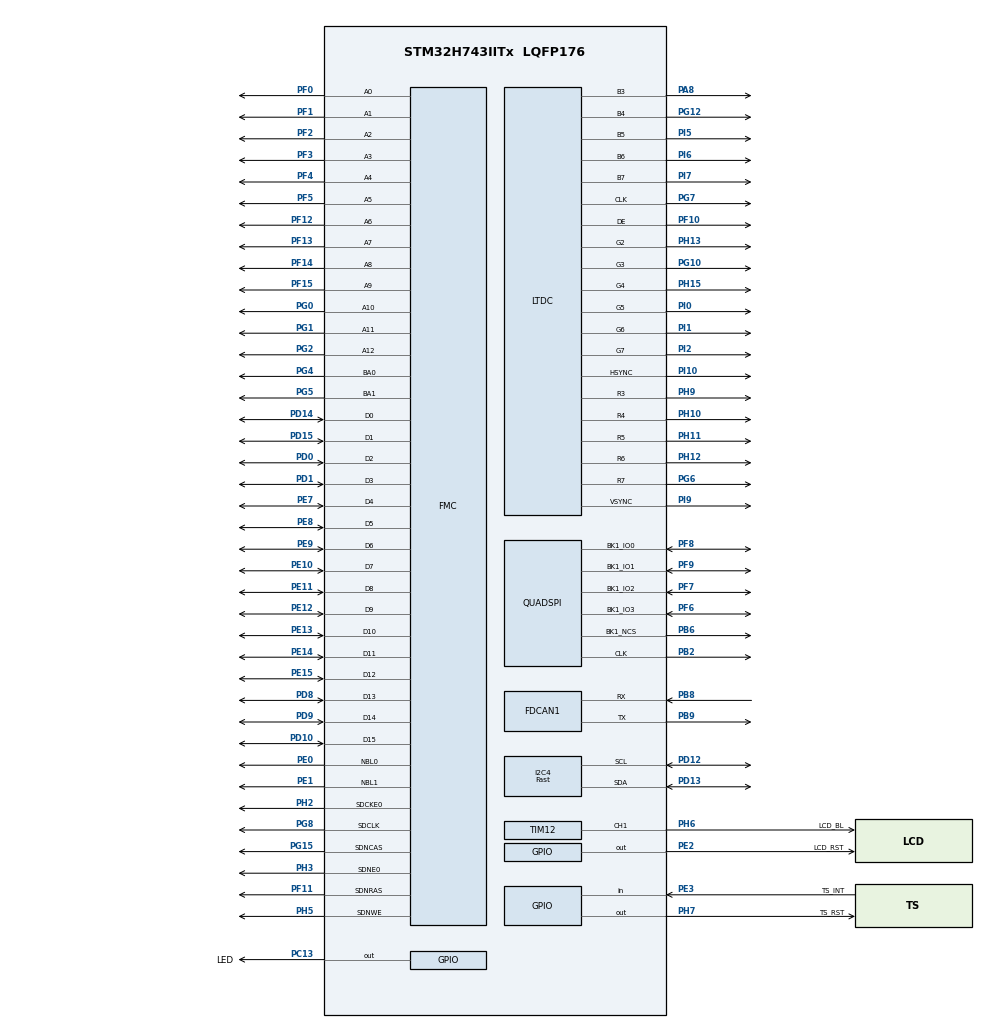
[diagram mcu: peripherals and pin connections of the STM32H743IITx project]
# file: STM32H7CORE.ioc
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CORTEX_M7.AccessPermission_S-Cortex_Memory_Protection_Unit_Region1_Settings_S=MPU_REGION_FULL_ACCESS
CORTEX_M7.BaseAddress_S-Cortex_Memory_Protection_Unit_Region1_Settings_S=0xC0000000
CORTEX_M7.CPU_DCache=Enabled
CORTEX_M7.CPU_ICache=Enabled
CORTEX_M7.Enable_S-Cortex_Memory_Protection_Unit_Region1_Settings_S=MPU_REGION_ENABLE
CORTEX_M7.IsCacheable_S-Cortex_Memory_Protection_Unit_Region1_Settings_S=MPU_ACCESS_CACHEABLE
CORTEX_M7.IsShareable_S-Cortex_Memory_Protection_Unit_Region1_Settings_S=MPU_ACCESS_SHAREABLE
CORTEX_M7.Size_S-Cortex_Memory_Protection_Unit_Region1_Settings_S=MPU_REGION_SIZE_32MB
CORTEX_M7.default_mode_Activation=1
DMA2D.ColorMode=DMA2D_OUTPUT_RGB565
FDCAN1.CalculateBaudRateNominal=500000
FDCAN1.CalculateTimeBitNominal=2000
FDCAN1.CalculateTimeQuantumNominal=50.0
FDCAN1.DataPrescaler=8
FDCAN1.DataSyncJumpWidth=5
FDCAN1.DataTimeSeg1=14
FDCAN1.DataTimeSeg2=5
FDCAN1.Mode=FDCAN_MODE_INTERNAL_LOOPBACK
FDCAN1.NominalPrescaler=4
FDCAN1.NominalSyncJumpWidth=5
FDCAN1.NominalTimeSeg1=34
FDCAN1.NominalTimeSeg2=5
FDCAN1.RxFifo0ElmtsNbr=1
FDCAN1.StdFiltersNbr=1
FDCAN1.TxFifoQueueElmtsNbr=1
FMC.CASLatency1=FMC_SDRAM_CAS_LATENCY_3
FMC.ExitSelfRefreshDelay1=7
FMC.LoadToActiveDelay1=2
FMC.RCDDelay1=2
FMC.RPDelay1=2
FMC.ReadBurst1=FMC_SDRAM_RBURST_ENABLE
FMC.RowCycleDelay1=7
FMC.SDClockPeriod1=FMC_SDRAM_CLOCK_PERIOD_2
FMC.SelfRefreshTime1=4
FMC.WriteRecoveryTime1=3
FREERTOS.Mutexes01=lvglMutex,Dynamic,NULL,Available
FREERTOS.Queues01=backlightQueue,4,uint16_t,0,Dynamic,NULL,NULL;canRxQueue,16,CAN_RxMessageTypeDef,0,Dynamic,NULL,NULL
FREERTOS.Tasks01=debugTask,24,128,DebugTask,Default,NULL,Dynamic,NULL,NULL;lvglTask,25,2048,LvglTask,Default,NULL,Dynamic,NULL,NULL;backlightTask,8,128,BacklightTask,Default,NULL,Dynamic,NULL,NULL;canRxTask,8,1024,CanRxTask,Default,NULL,Dynamic,NULL,NULL;weakTask,8,128,WeakTask,As weak,NULL,Dynamic,NULL,NULL;externTask,8,128,ExternTask,As external,NULL,Dynamic,NULL,NULL
FREERTOS.configENABLE_FPU=1
FREERTOS.configTOTAL_HEAP_SIZE=64000
I2C4.I2C_Speed_Mode=I2C_Fast
I2C4.Timing=0x00B03FDB
LTDC.ActiveH=600
LTDC.ActiveW=1024
LTDC.Alpha_L0=255
LTDC.FBStartAdress_L0=0xC0000000
LTDC.HBP=46
LTDC.HFP=40
LTDC.HSync=1
LTDC.ImageHeight_L0=600
LTDC.ImageWidth_L0=1024
LTDC.Layers=0
LTDC.PixelFormat_L0=LTDC_PIXEL_FORMAT_RGB565
LTDC.VBP=24
LTDC.VFP=10
LTDC.VSync=2
LTDC.WindowX1_L0=1024
LTDC.WindowY1_L0=600
Mcu.Family=STM32H7
Mcu.Name=STM32H743IITx
Mcu.Package=LQFP176
NVIC.FDCAN1_IT0_IRQn=true\:5\:0\:false\:false\:true\:true\:true\:true\:true
NVIC.PriorityGroup=NVIC_PRIORITYGROUP_4
NVIC.TIM6_DAC_IRQn=true\:15\:0\:false\:false\:true\:false\:false\:true\:true
NVIC.TimeBase=TIM6_DAC_IRQn
NVIC.TimeBaseIP=TIM6
PA13\ (JTMS/SWDIO).Mode=Serial_Wire
PA13\ (JTMS/SWDIO).Signal=DEBUG_JTMS-SWDIO
PA14\ (JTCK/SWCLK).Mode=Serial_Wire
PA14\ (JTCK/SWCLK).Signal=DEBUG_JTCK-SWCLK
PA8.GPIO_Speed=GPIO_SPEED_FREQ_VERY_HIGH
PA8.Mode=RGB565
PA8.Signal=LTDC_B3
PB2.Mode=Single Bank 1
PB2.Signal=QUADSPI_CLK
PB6.Mode=Single Bank 1
PB6.Signal=QUADSPI_BK1_NCS
PB8.GPIO_Speed=GPIO_SPEED_FREQ_VERY_HIGH
PB8.Mode=FDCAN_Activate
PB8.Signal=FDCAN1_RX
PB9.GPIO_Speed=GPIO_SPEED_FREQ_VERY_HIGH
PB9.Mode=FDCAN_Activate
PB9.Signal=FDCAN1_TX
PC13.GPIO_Label=LED
PC13.Signal=GPIO_Output
PC14-OSC32_IN\ (OSC32_IN).Mode=LSE-External-Oscillator
PC14-OSC32_IN\ (OSC32_IN).Signal=RCC_OSC32_IN
PC15-OSC32_OUT\ (OSC32_OUT).Mode=LSE-External-Oscillator
PC15-OSC32_OUT\ (OSC32_OUT).Signal=RCC_OSC32_OUT
PD0.Signal=FMC_D2_DA2
PD1.Signal=FMC_D3_DA3
PD10.Signal=FMC_D15_DA15
PD12.Mode=I2C
PD12.Signal=I2C4_SCL
PD13.Mode=I2C
PD13.Signal=I2C4_SDA
PD14.Signal=FMC_D0_DA0
PD15.Signal=FMC_D1_DA1
PD8.Signal=FMC_D13_DA13
PD9.Signal=FMC_D14_DA14
PE0.Signal=FMC_NBL0
PE1.Signal=FMC_NBL1
PE10.Signal=FMC_D7_DA7
PE11.Signal=FMC_D8_DA8
PE12.Signal=FMC_D9_DA9
PE13.Signal=FMC_D10_DA10
PE14.Signal=FMC_D11_DA11
PE15.Signal=FMC_D12_DA12
PE2.GPIO_Label=LCD_RST
PE2.PinState=GPIO_PIN_SET
PE2.Signal=GPIO_Output
PE3.GPIO_Label=TS_INT
PE3.Signal=GPIO_Input
PE7.Signal=FMC_D4_DA4
PE8.Signal=FMC_D5_DA5
PE9.Signal=FMC_D6_DA6
PF0.Signal=FMC_A0
PF1.Signal=FMC_A1
PF10.GPIO_Speed=GPIO_SPEED_FREQ_VERY_HIGH
PF10.Mode=RGB565
PF10.Signal=LTDC_DE
PF11.Signal=FMC_SDNRAS
PF12.Signal=FMC_A6
PF13.Signal=FMC_A7
PF14.Signal=FMC_A8
PF15.Signal=FMC_A9
PF2.Signal=FMC_A2
PF3.Signal=FMC_A3
PF4.Signal=FMC_A4
PF5.Signal=FMC_A5
PF6.Mode=Single Bank 1
PF6.Signal=QUADSPI_BK1_IO3
PF7.Mode=Single Bank 1
PF7.Signal=QUADSPI_BK1_IO2
PF8.Mode=Single Bank 1
PF8.Signal=QUADSPI_BK1_IO0
PF9.Mode=Single Bank 1
PF9.Signal=QUADSPI_BK1_IO1
PG0.Signal=FMC_A10
PG1.Signal=FMC_A11
PG10.GPIO_Speed=GPIO_SPEED_FREQ_VERY_HIGH
PG10.Mode=RGB565
PG10.Signal=LTDC_G3
PG12.GPIO_Speed=GPIO_SPEED_FREQ_VERY_HIGH
PG12.Mode=RGB565
PG12.Signal=LTDC_B4
PG15.Signal=FMC_SDNCAS
PG2.Signal=FMC_A12
PG4.Signal=FMC_A14_BA0
PG5.Signal=FMC_A15_BA1
PG6.GPIO_Speed=GPIO_SPEED_FREQ_VERY_HIGH
PG6.Mode=RGB565
PG6.Signal=LTDC_R7
PG7.GPIO_Speed=GPIO_SPEED_FREQ_VERY_HIGH
PG7.Mode=RGB565
PG7.Signal=LTDC_CLK
PG8.Signal=FMC_SDCLK
PH0-OSC_IN\ (PH0).Mode=HSE-External-Oscillator
PH0-OSC_IN\ (PH0).Signal=RCC_OSC_IN
PH1-OSC_OUT\ (PH1).Mode=HSE-External-Oscillator
PH1-OSC_OUT\ (PH1).Signal=RCC_OSC_OUT
PH10.GPIO_Speed=GPIO_SPEED_FREQ_VERY_HIGH
PH10.Mode=RGB565
PH10.Signal=LTDC_R4
PH11.GPIO_Speed=GPIO_SPEED_FREQ_VERY_HIGH
PH11.Mode=RGB565
PH11.Signal=LTDC_R5
PH12.GPIO_Speed=GPIO_SPEED_FREQ_VERY_HIGH
PH12.Mode=RGB565
PH12.Signal=LTDC_R6
PH13.GPIO_Speed=GPIO_SPEED_FREQ_VERY_HIGH
PH13.Mode=RGB565
PH13.Signal=LTDC_G2
PH15.GPIO_Speed=GPIO_SPEED_FREQ_VERY_HIGH
PH15.Mode=RGB565
PH15.Signal=LTDC_G4
PH2.Mode=SdramChipSelect1_1
PH2.Signal=FMC_SDCKE0
PH3.Mode=SdramChipSelect1_1
PH3.Signal=FMC_SDNE0
PH5.Signal=FMC_SDNWE
PH6.GPIO_Label=LCD_BL
PH6.Signal=S_TIM12_CH1
PH7.GPIO_Label=TS_RST
PH7.Signal=GPIO_Output
PH9.GPIO_Speed=GPIO_SPEED_FREQ_VERY_HIGH
PH9.Mode=RGB565
PH9.Signal=LTDC_R3
PI0.GPIO_Speed=GPIO_SPEED_FREQ_VERY_HIGH
PI0.Mode=RGB565
PI0.Signal=LTDC_G5
PI1.GPIO_Speed=GPIO_SPEED_FREQ_VERY_HIGH
PI1.Mode=RGB565
PI1.Signal=LTDC_G6
PI10.GPIO_Speed=GPIO_SPEED_FREQ_VERY_HIGH
PI10.Mode=RGB565
PI10.Signal=LTDC_HSYNC
PI2.GPIO_Speed=GPIO_SPEED_FREQ_VERY_HIGH
PI2.Mode=RGB565
PI2.Signal=LTDC_G7
PI5.GPIO_Speed=GPIO_SPEED_FREQ_VERY_HIGH
PI5.Mode=RGB565
PI5.Signal=LTDC_B5
PI6.GPIO_Speed=GPIO_SPEED_FREQ_VERY_HIGH
PI6.Mode=RGB565
PI6.Signal=LTDC_B6
PI7.GPIO_Speed=GPIO_SPEED_FREQ_VERY_HIGH
PI7.Mode=RGB565
PI7.Signal=LTDC_B7
PI9.GPIO_Speed=GPIO_SPEED_FREQ_VERY_HIGH
PI9.Mode=RGB565
PI9.Signal=LTDC_VSYNC
ProjectManager.HeapSize=0x200
ProjectManager.StackSize=0x400
ProjectManager.TargetToolchain=CMake
QUADSPI.ClockPrescaler=1
QUADSPI.FifoThreshold=4
QUADSPI.FlashSize=23
QUADSPI.SampleShifting=QSPI_SAMPLE_SHIFTING_NONE
RCC.ADCFreq_Value=50390625
RCC.APB1Freq_Value=120000000
RCC.APB2Freq_Value=120000000
RCC.APB3Freq_Value=120000000
RCC.APB4Freq_Value=120000000
RCC.CortexFreq_Value=480000000
RCC.D1PPRE=RCC_APB3_DIV2
RCC.D2PPRE1=RCC_APB1_DIV2
RCC.D2PPRE2=RCC_APB2_DIV2
RCC.D3PPRE=RCC_APB4_DIV2
RCC.DIVM1=5
RCC.DIVM3=1
RCC.DIVN1=192
RCC.DIVN3=6
RCC.DIVQ1=12
RCC.DIVR3=6
RCC.HCLKFreq_Value=240000000
RCC.HPRE=RCC_HCLK_DIV2
RCC.PLL3FRACN=0
RCC.PLLFRACN=0
RCC.PLLSourceVirtual=RCC_PLLSOURCE_HSE
RCC.SYSCLKFreq_VALUE=480000000
RCC.SYSCLKSource=RCC_SYSCLKSOURCE_PLLCLK
RCC.USBFreq_Value=80000000
SH.FMC_A0.0=FMC_A0,13b-sda1
SH.FMC_A1.0=FMC_A1,13b-sda1
SH.FMC_A10.0=FMC_A10,13b-sda1
SH.FMC_A11.0=FMC_A11,13b-sda1
SH.FMC_A12.0=FMC_A12,13b-sda1
SH.FMC_A14_BA0.0=FMC_BA0,FourSdramBanks1
SH.FMC_A15_BA1.0=FMC_BA1,FourSdramBanks1
SH.FMC_A2.0=FMC_A2,13b-sda1
SH.FMC_A3.0=FMC_A3,13b-sda1
SH.FMC_A4.0=FMC_A4,13b-sda1
SH.FMC_A5.0=FMC_A5,13b-sda1
SH.FMC_A6.0=FMC_A6,13b-sda1
SH.FMC_A7.0=FMC_A7,13b-sda1
SH.FMC_A8.0=FMC_A8,13b-sda1
SH.FMC_A9.0=FMC_A9,13b-sda1
SH.FMC_D0_DA0.0=FMC_D0,sd-16b-d1
SH.FMC_D10_DA10.0=FMC_D10,sd-16b-d1
SH.FMC_D11_DA11.0=FMC_D11,sd-16b-d1
SH.FMC_D12_DA12.0=FMC_D12,sd-16b-d1
SH.FMC_D13_DA13.0=FMC_D13,sd-16b-d1
SH.FMC_D14_DA14.0=FMC_D14,sd-16b-d1
SH.FMC_D15_DA15.0=FMC_D15,sd-16b-d1
SH.FMC_D1_DA1.0=FMC_D1,sd-16b-d1
SH.FMC_D2_DA2.0=FMC_D2,sd-16b-d1
SH.FMC_D3_DA3.0=FMC_D3,sd-16b-d1
SH.FMC_D4_DA4.0=FMC_D4,sd-16b-d1
SH.FMC_D5_DA5.0=FMC_D5,sd-16b-d1
SH.FMC_D6_DA6.0=FMC_D6,sd-16b-d1
SH.FMC_D7_DA7.0=FMC_D7,sd-16b-d1
SH.FMC_D8_DA8.0=FMC_D8,sd-16b-d1
SH.FMC_D9_DA9.0=FMC_D9,sd-16b-d1
SH.FMC_NBL0.0=FMC_NBL0,Sd2ByteEnable1
SH.FMC_NBL1.0=FMC_NBL1,Sd2ByteEnable1
SH.FMC_SDCLK.0=FMC_SDCLK,13b-sda1
SH.FMC_SDNCAS.0=FMC_SDNCAS,13b-sda1
SH.FMC_SDNRAS.0=FMC_SDNRAS,13b-sda1
SH.FMC_SDNWE.0=FMC_SDNWE,13b-sda1
SH.S_TIM12_CH1.0=TIM12_CH1,PWM Generation1 CH1
TIM12.Channel-PWM\ Generation1\ CH1=TIM_CHANNEL_1
TIM12.Period=99
TIM12.Prescaler=9999
TIM12.Pulse-PWM\ Generation1\ CH1=20
VP_DMA2D_VS_DMA2D.Mode=DMA2D_Activate
VP_FREERTOS_VS_CMSIS_V2.Mode=CMSIS_V2
VP_MEMORYMAP_VS_MEMORYMAP.Mode=CurAppReg
VP_SYS_VS_tim6.Mode=TIM6
VP_TIM12_VS_ClockSourceINT.Mode=Internal
board=custom

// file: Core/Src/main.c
/* USER CODE BEGIN Header */
/**
  ******************************************************************************
  * @file           : main.c
  * @brief          : Main program body
  ******************************************************************************
  * @attention
  *
  * Copyright (c) 2025 STMicroelectronics.
  * All rights reserved.
  *
  * This software is licensed under terms that can be found in the LICENSE file
  * in the root directory of this software component.
  * If no LICENSE file comes with this software, it is provided AS-IS.
  *
  ******************************************************************************
  */
/* USER CODE END Header */
#include "main.h"
#include "cmsis_os.h"
#include "dma2d.h"
#include "fdcan.h"
#include "i2c.h"
#include "ltdc.h"
#include "quadspi.h"
#include "tim.h"
#include "gpio.h"
#include "fmc.h"

/* USER CODE BEGIN Includes */
#include <string.h>

#include "bsp.h"
/* USER CODE END Includes */

/* USER CODE BEGIN PV */
extern osMessageQueueId_t canRxQueueHandle;
extern osThreadId_t externTaskHandle;
/* USER CODE END PV */

void SystemClock_Config(void);
static void MPU_Config(void);
void MX_FREERTOS_Init(void);

/* USER CODE BEGIN 0 */
void HAL_FDCAN_RxFifo0Callback(FDCAN_HandleTypeDef *hfdcan, uint32_t RxFifo0ITs) {
    if ((RxFifo0ITs & FDCAN_IT_RX_FIFO0_NEW_MESSAGE) != RESET) {
        FDCAN_RxHeaderTypeDef RxHeader;
        uint8_t RxBuffer[8];
        HAL_FDCAN_GetRxMessage(hfdcan, FDCAN_RX_FIFO0, &RxHeader, RxBuffer);

        CAN_RxMessageTypeDef CAN_RxMessage;
        CAN_RxMessage.ID = RxHeader.Identifier;
        memcpy(CAN_RxMessage.Data, RxBuffer, 8);
        osMessageQueuePut(canRxQueueHandle, &CAN_RxMessage, 0, 0);
    }
}

void ExternTask(void const * argument) {
  osThreadSuspend(externTaskHandle);
  for (;;) {
    HAL_GPIO_TogglePin(LED_GPIO_Port, LED_Pin);
    osDelay(500);
  }
}
/* USER CODE END 0 */

int main(void)
{

  /* MPU Configuration--------------------------------------------------------*/
  MPU_Config();

  /* Enable the CPU Cache */

  /* Enable I-Cache---------------------------------------------------------*/
  SCB_EnableICache();

  /* Enable D-Cache---------------------------------------------------------*/
  SCB_EnableDCache();

  /* MCU Configuration--------------------------------------------------------*/

  /* Reset of all peripherals, Initializes the Flash interface and the Systick. */
  HAL_Init();

  /* Configure the system clock */
  SystemClock_Config();

  /* Initialize all configured peripherals */
  MX_GPIO_Init();
  MX_FMC_Init();
  MX_I2C4_Init();
  MX_LTDC_Init();
  MX_DMA2D_Init();
  MX_TIM12_Init();
  MX_FDCAN1_Init();
  MX_QUADSPI_Init();
  /* USER CODE BEGIN 2 */
    BSP_Init();
    HAL_FDCAN_Start(&hfdcan1);
    HAL_FDCAN_ActivateNotification(&hfdcan1, FDCAN_IT_RX_FIFO0_NEW_MESSAGE, 0);
  /* USER CODE END 2 */

  /* Init scheduler */
  osKernelInitialize();  /* Call init function for freertos objects (in cmsis_os2.c) */
  MX_FREERTOS_Init();

  /* Start scheduler */
  osKernelStart();

  /* We should never get here as control is now taken by the scheduler */

  /* Infinite loop */
    while (1) {

    }
}

void SystemClock_Config(void)
{
  RCC_OscInitTypeDef RCC_OscInitStruct = {0};
  RCC_ClkInitTypeDef RCC_ClkInitStruct = {0};

  /** Supply configuration update enable
  */
  HAL_PWREx_ConfigSupply(PWR_LDO_SUPPLY);

  /** Configure the main internal regulator output voltage
  */
  __HAL_PWR_VOLTAGESCALING_CONFIG(PWR_REGULATOR_VOLTAGE_SCALE0);

  while(!__HAL_PWR_GET_FLAG(PWR_FLAG_VOSRDY)) {}

  /** Initializes the RCC Oscillators according to the specified parameters
  * in the RCC_OscInitTypeDef structure.
  */
  RCC_OscInitStruct.OscillatorType = RCC_OSCILLATORTYPE_HSE;
  RCC_OscInitStruct.HSEState = RCC_HSE_ON;
  RCC_OscInitStruct.PLL.PLLState = RCC_PLL_ON;
  RCC_OscInitStruct.PLL.PLLSource = RCC_PLLSOURCE_HSE;
  RCC_OscInitStruct.PLL.PLLM = 5;
  RCC_OscInitStruct.PLL.PLLN = 192;
  RCC_OscInitStruct.PLL.PLLP = 2;
  RCC_OscInitStruct.PLL.PLLQ = 12;
  RCC_OscInitStruct.PLL.PLLR = 2;
  RCC_OscInitStruct.PLL.PLLRGE = RCC_PLL1VCIRANGE_2;
  RCC_OscInitStruct.PLL.PLLVCOSEL = RCC_PLL1VCOWIDE;
  RCC_OscInitStruct.PLL.PLLFRACN = 0;
  if (HAL_RCC_OscConfig(&RCC_OscInitStruct) != HAL_OK)
  {
    Error_Handler();
  }

  /** Initializes the CPU, AHB and APB buses clocks
  */
  RCC_ClkInitStruct.ClockType = RCC_CLOCKTYPE_HCLK|RCC_CLOCKTYPE_SYSCLK
                              |RCC_CLOCKTYPE_PCLK1|RCC_CLOCKTYPE_PCLK2
                              |RCC_CLOCKTYPE_D3PCLK1|RCC_CLOCKTYPE_D1PCLK1;
  RCC_ClkInitStruct.SYSCLKSource = RCC_SYSCLKSOURCE_PLLCLK;
  RCC_ClkInitStruct.SYSCLKDivider = RCC_SYSCLK_DIV1;
  RCC_ClkInitStruct.AHBCLKDivider = RCC_HCLK_DIV2;
  RCC_ClkInitStruct.APB3CLKDivider = RCC_APB3_DIV2;
  RCC_ClkInitStruct.APB1CLKDivider = RCC_APB1_DIV2;
  RCC_ClkInitStruct.APB2CLKDivider = RCC_APB2_DIV2;
  RCC_ClkInitStruct.APB4CLKDivider = RCC_APB4_DIV2;

  if (HAL_RCC_ClockConfig(&RCC_ClkInitStruct, FLASH_LATENCY_4) != HAL_OK)
  {
    Error_Handler();
  }
}

 /* MPU Configuration */

void MPU_Config(void)
{
  MPU_Region_InitTypeDef MPU_InitStruct = {0};

  /* Disables the MPU */
  HAL_MPU_Disable();

  /** Initializes and configures the Region and the memory to be protected
  */
  MPU_InitStruct.Enable = MPU_REGION_ENABLE;
  MPU_InitStruct.Number = MPU_REGION_NUMBER0;
  MPU_InitStruct.BaseAddress = 0x0;
  MPU_InitStruct.Size = MPU_REGION_SIZE_4GB;
  MPU_InitStruct.SubRegionDisable = 0x87;
  MPU_InitStruct.TypeExtField = MPU_TEX_LEVEL0;
  MPU_InitStruct.AccessPermission = MPU_REGION_NO_ACCESS;
  MPU_InitStruct.DisableExec = MPU_INSTRUCTION_ACCESS_DISABLE;
  MPU_InitStruct.IsShareable = MPU_ACCESS_SHAREABLE;
  MPU_InitStruct.IsCacheable = MPU_ACCESS_NOT_CACHEABLE;
  MPU_InitStruct.IsBufferable = MPU_ACCESS_NOT_BUFFERABLE;

  HAL_MPU_ConfigRegion(&MPU_InitStruct);

  /** Initializes and configures the Region and the memory to be protected
  */
  MPU_InitStruct.Number = MPU_REGION_NUMBER1;
  MPU_InitStruct.BaseAddress = 0xC0000000;
  MPU_InitStruct.Size = MPU_REGION_SIZE_32MB;
  MPU_InitStruct.SubRegionDisable = 0x0;
  MPU_InitStruct.AccessPermission = MPU_REGION_FULL_ACCESS;
  MPU_InitStruct.DisableExec = MPU_INSTRUCTION_ACCESS_ENABLE;
  MPU_InitStruct.IsCacheable = MPU_ACCESS_CACHEABLE;

  HAL_MPU_ConfigRegion(&MPU_InitStruct);
  /* Enables the MPU */
  HAL_MPU_Enable(MPU_PRIVILEGED_DEFAULT);

}

void HAL_TIM_PeriodElapsedCallback(TIM_HandleTypeDef *htim)
{
  if (htim->Instance == TIM6)
  {
    HAL_IncTick();
  }
}

void Error_Handler(void)
{
    __disable_irq();
    while (1) {
    }
}

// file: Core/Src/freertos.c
/* USER CODE BEGIN Header */
/**
  ******************************************************************************
  * File Name          : freertos.c
  * Description        : Code for freertos applications
  ******************************************************************************
  * @attention
  *
  * Copyright (c) 2025 STMicroelectronics.
  * All rights reserved.
  *
  * This software is licensed under terms that can be found in the LICENSE file
  * in the root directory of this software component.
  * If no LICENSE file comes with this software, it is provided AS-IS.
  *
  ******************************************************************************
  */
/* USER CODE END Header */

#include "FreeRTOS.h"
#include "task.h"
#include "main.h"
#include "cmsis_os.h"

/* USER CODE BEGIN Includes */
#include "lv_port_display.h"
#include "ui.h"
#include "actions.h"
#include "tim.h"
#include "fdcan.h"
/* USER CODE END Includes */

/* USER CODE BEGIN Variables */
uint8_t can_data_msg = 0;
/* USER CODE END Variables */
/* Definitions for debugTask */
osThreadId_t debugTaskHandle;
const osThreadAttr_t debugTask_attributes = {
  .name = "debugTask",
  .stack_size = 128 * 4,
  .priority = (osPriority_t) osPriorityNormal,
};
/* Definitions for lvglTask */
osThreadId_t lvglTaskHandle;
const osThreadAttr_t lvglTask_attributes = {
  .name = "lvglTask",
  .stack_size = 2048 * 4,
  .priority = (osPriority_t) osPriorityNormal1,
};
/* Definitions for backlightTask */
osThreadId_t backlightTaskHandle;
const osThreadAttr_t backlightTask_attributes = {
  .name = "backlightTask",
  .stack_size = 128 * 4,
  .priority = (osPriority_t) osPriorityLow,
};
/* Definitions for canRxTask */
osThreadId_t canRxTaskHandle;
const osThreadAttr_t canRxTask_attributes = {
  .name = "canRxTask",
  .stack_size = 1024 * 4,
  .priority = (osPriority_t) osPriorityLow,
};
/* Definitions for weakTask */
osThreadId_t weakTaskHandle;
const osThreadAttr_t weakTask_attributes = {
  .name = "weakTask",
  .stack_size = 128 * 4,
  .priority = (osPriority_t) osPriorityLow,
};
/* Definitions for externTask */
osThreadId_t externTaskHandle;
const osThreadAttr_t externTask_attributes = {
  .name = "externTask",
  .stack_size = 128 * 4,
  .priority = (osPriority_t) osPriorityLow,
};
/* Definitions for backlightQueue */
osMessageQueueId_t backlightQueueHandle;
const osMessageQueueAttr_t backlightQueue_attributes = {
  .name = "backlightQueue"
};
/* Definitions for canRxQueue */
osMessageQueueId_t canRxQueueHandle;
const osMessageQueueAttr_t canRxQueue_attributes = {
  .name = "canRxQueue"
};
/* Definitions for lvglMutex */
osMutexId_t lvglMutexHandle;
const osMutexAttr_t lvglMutex_attributes = {
  .name = "lvglMutex"
};

/* USER CODE BEGIN FunctionPrototypes */
void my_timer(lv_timer_t *timer);

/* USER CODE END FunctionPrototypes */

void DebugTask(void *argument);
void LvglTask(void *argument);
void BacklightTask(void *argument);
void CanRxTask(void *argument);
void WeakTask(void *argument);
extern void ExternTask(void *argument);

void MX_FREERTOS_Init(void); /* (MISRA C 2004 rule 8.1) */

void MX_FREERTOS_Init(void) {
  /* Create the mutex(es) */
  /* creation of lvglMutex */
  lvglMutexHandle = osMutexNew(&lvglMutex_attributes);

  /* Create the queue(s) */
  /* creation of backlightQueue */
  backlightQueueHandle = osMessageQueueNew (4, sizeof(uint16_t), &backlightQueue_attributes);

  /* creation of canRxQueue */
  canRxQueueHandle = osMessageQueueNew (16, sizeof(CAN_RxMessageTypeDef), &canRxQueue_attributes);

  /* Create the thread(s) */
  /* creation of debugTask */
  debugTaskHandle = osThreadNew(DebugTask, NULL, &debugTask_attributes);

  /* creation of lvglTask */
  lvglTaskHandle = osThreadNew(LvglTask, NULL, &lvglTask_attributes);

  /* creation of backlightTask */
  backlightTaskHandle = osThreadNew(BacklightTask, NULL, &backlightTask_attributes);

  /* creation of canRxTask */
  canRxTaskHandle = osThreadNew(CanRxTask, NULL, &canRxTask_attributes);

  /* creation of weakTask */
  weakTaskHandle = osThreadNew(WeakTask, NULL, &weakTask_attributes);

  /* creation of externTask */
  externTaskHandle = osThreadNew(ExternTask, NULL, &externTask_attributes);

}

void DebugTask(void *argument)
{
  /* USER CODE BEGIN DebugTask */
    FDCAN_TxHeaderTypeDef TxHeader;
    uint8_t TxBuffer[8];

    TxHeader.Identifier = 0x321;
    TxHeader.IdType = FDCAN_STANDARD_ID;
    TxHeader.TxFrameType = FDCAN_DATA_FRAME;
    TxHeader.DataLength = FDCAN_DLC_BYTES_8;
    TxHeader.ErrorStateIndicator = FDCAN_ESI_PASSIVE;
    TxHeader.BitRateSwitch = FDCAN_BRS_OFF;
    TxHeader.FDFormat = FDCAN_CLASSIC_CAN;
    TxHeader.TxEventFifoControl = FDCAN_NO_TX_EVENTS;
    TxHeader.MessageMarker = 0;

    TxBuffer[0] = 0x00;
    /* Infinite loop */
    for (;;) {
        TxBuffer[0]++;
        HAL_FDCAN_AddMessageToTxFifoQ(&hfdcan1, &TxHeader, TxBuffer);
        osDelay(100);
    }
  /* USER CODE END DebugTask */
}

void LvglTask(void *argument)
{
  /* USER CODE BEGIN LvglTask */
    lv_port_display_init();
    ui_init();
    // lv_timer_t *timer = lv_timer_create(my_timer, 100,  NULL);
    // lv_timer_set_repeat_count(timer, -1);
    /* Infinite loop */
    for (;;) {
        osMutexAcquire(lvglMutexHandle, osWaitForever);
        lv_timer_handler();
        osMutexRelease(lvglMutexHandle);
        osDelay(5);
    }
  /* USER CODE END LvglTask */
}

void BacklightTask(void *argument)
{
  /* USER CODE BEGIN BacklightTask */
    uint16_t backlight_level;
    /* Infinite loop */
    for (;;) {
        if (osMessageQueueGet(backlightQueueHandle, &backlight_level, 0, osWaitForever) == osOK) {
            __HAL_TIM_SET_COMPARE(&htim12, TIM_CHANNEL_1, backlight_level);
        }
        osDelay(1);
    }
  /* USER CODE END BacklightTask */
}

void CanRxTask(void *argument)
{
  /* USER CODE BEGIN CanRxTask */
    CAN_RxMessageTypeDef CAN_RxMessage;

    /* Infinite loop */
    for (;;) {
        if (osMessageQueueGet(canRxQueueHandle, &CAN_RxMessage, 0, osWaitForever) == osOK) {
            osMutexAcquire(lvglMutexHandle, osWaitForever);

            can_data_msg = CAN_RxMessage.Data[0];
            lv_label_set_text_fmt(objects.label, "%d", can_data_msg);
            if (can_data_msg == 128) {
                lv_obj_set_flag(objects.loading, LV_OBJ_FLAG_HIDDEN, true);
                osThreadSuspend(externTaskHandle);
            }
            osMutexRelease(lvglMutexHandle);
        }
        osDelay(1);
    }
  /* USER CODE END CanRxTask */
}

__weak void WeakTask(void *argument)
{
    for (;;) {
        osDelay(1);
    }
}

/* USER CODE BEGIN Application */
void action_set_backlight(lv_event_t *e) {
    lv_obj_t *obj = lv_event_get_target(e);
    uint16_t backlight = lv_slider_get_value(obj);
    osMessageQueuePut(backlightQueueHandle, &backlight, 0, osWaitForever);
}

void action_reset_backlight(lv_event_t *e) {
    uint16_t backlight = 20;
    lv_slider_set_value(objects.backlight_slider, backlight, LV_ANIM_OFF);
    osMessageQueuePut(backlightQueueHandle, &backlight, 0, osWaitForever);
}

void action_change_theme(lv_event_t *e) {
    static bool is_dark = false;
    is_dark = !is_dark;
    lv_theme_t *theme = lv_theme_default_init(NULL, lv_palette_main(LV_PALETTE_BLUE),
                                              lv_palette_main(LV_PALETTE_BLUE_GREY), is_dark, &lv_font_montserrat_14);
    lv_display_set_theme(NULL, theme);
}

void my_timer(lv_timer_t *timer) {
    lv_label_set_text_fmt(objects.label, "%d", can_data_msg);
}

void action_set_loading(lv_event_t *e) {
    lv_obj_set_flag(objects.loading, LV_OBJ_FLAG_HIDDEN, false);
    osThreadResume(externTaskHandle);
}

/* USER CODE END Application */
